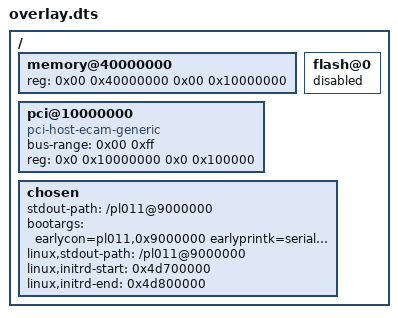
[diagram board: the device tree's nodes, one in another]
/*
 * Copyright 2024, UNSW
 *
 * SPDX-License-Identifier: BSD-2-Clause
 */
/ {
    /* Need to specify how much RAM the guest will have */
    memory@40000000 {
        device_type = "memory";
        reg = <0x00 0x40000000 0x00 0x10000000>;
    };

    flash@0 {
        status = "disabled";
    };

    pci@10000000 {
        compatible = "pci-host-ecam-generic";
        device_type = "pci";
        #address-cells = <3>;
        #size-cells = <2>;
        #interrupt-cells = <1>;

        /* PCI bus range */
        bus-range = <0x00 0xff>;

        /* Register space for ECAM configuration */
        reg = <0x0 0x10000000 0x0 0x100000>;  /* 256MB ECAM space */

        /* Memory and I/O ranges */
        ranges = <0x02000000 0x0 0x20100000  0x0 0x20100000  0x0 0x0ff00000>;  /* 32-bit memory */

        /* <0x01000000 0x0 0x00000000  0x0 0x20000000  0x0 0x00100000>, */  /* I/O space */
        /* <0x43000000 0x4 0x00000000  0x4 0x00000000  0x1 0x00000000>; */ /* 64-bit memory */

        /* Interrupt mapping */
        /* interrupt-map-mask = <0x1800 0x0 0x0 0x7>; */
        /* interrupt-map = <0x0000 0x0 0x0 0x1 &gic GIC_SPI 3 IRQ_TYPE_LEVEL_HIGH>, */
        /*                 <0x0000 0x0 0x0 0x2 &gic GIC_SPI 4 IRQ_TYPE_LEVEL_HIGH>, */
        /*                 <0x0000 0x0 0x0 0x3 &gic GIC_SPI 5 IRQ_TYPE_LEVEL_HIGH>, */
        /*                 <0x0000 0x0 0x0 0x4 &gic GIC_SPI 6 IRQ_TYPE_LEVEL_HIGH>; */

        /* MSI controller reference (optional) */
        /* msi-parent = <&its>; */
    };

    chosen {
        stdout-path = "/pl011@9000000";
        bootargs = "earlycon=pl011,0x9000000 earlyprintk=serial debug loglevel=8";
        linux,stdout-path = "/pl011@9000000";
        linux,initrd-start = <0x4d700000>;
        linux,initrd-end = <0x4d800000>;
    };
};
